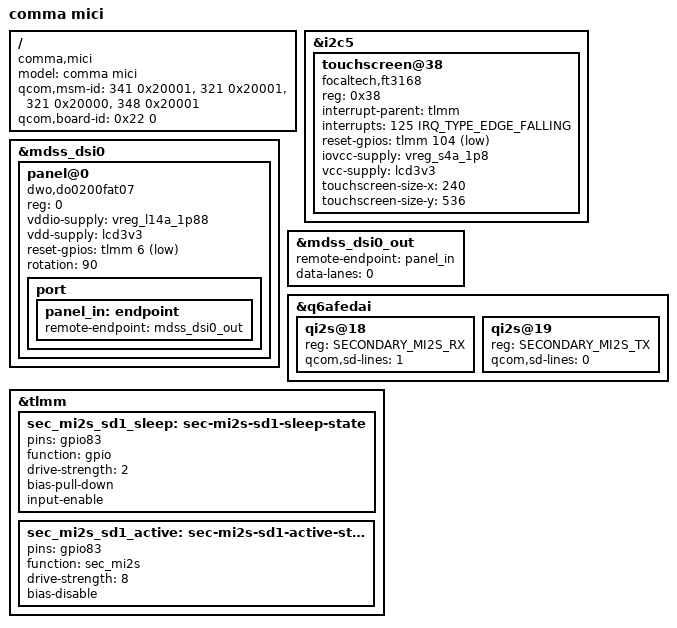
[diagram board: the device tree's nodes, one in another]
/dts-v1/;

#include "sdm845-comma-common.dtsi"

/ {
	model = "comma mici";
	compatible = "comma,mici", "qcom,sdm845";
	qcom,msm-id = <341 0x20001>, <321 0x20001>, <321 0x20000>, <348 0x20001>;
	qcom,board-id = <0x22 0>;
};

&i2c5 {
	touchscreen@38 {
		compatible = "focaltech,ft3168";
		reg = <0x38>;

		interrupt-parent = <&tlmm>;
		interrupts = <125 IRQ_TYPE_EDGE_FALLING>;
		reset-gpios = <&tlmm 104 GPIO_ACTIVE_LOW>;

		iovcc-supply = <&vreg_s4a_1p8>;
		vcc-supply = <&lcd3v3>;

		touchscreen-size-x = <240>;
		touchscreen-size-y = <536>;
	};
};

&mdss_dsi0 {
	panel@0 {
		compatible = "dwo,do0200fat07";

		reg = <0>;

		vddio-supply = <&vreg_l14a_1p88>;
		vdd-supply = <&lcd3v3>;

		reset-gpios = <&tlmm 6 GPIO_ACTIVE_LOW>;

		rotation = <90>;

		port {
			panel_in: endpoint {
				remote-endpoint = <&mdss_dsi0_out>;
			};
		};
	};
};

&mdss_dsi0_out {
	remote-endpoint = <&panel_in>;
	data-lanes = <0>;
};

&q6afedai {
	qi2s@18 {
		reg = <SECONDARY_MI2S_RX>;
		qcom,sd-lines = <1>;
	};

	qi2s@19 {
		reg = <SECONDARY_MI2S_TX>;
		qcom,sd-lines = <0>;
	};
};

&tlmm {
	sec_mi2s_sd1_sleep: sec-mi2s-sd1-sleep-state {
		pins = "gpio83";
		function = "gpio";
		drive-strength = <2>;
		bias-pull-down;
		input-enable;
	};

	sec_mi2s_sd1_active: sec-mi2s-sd1-active-state {
		pins = "gpio83";
		function = "sec_mi2s";
		drive-strength = <8>;
		bias-disable;
	};
};
